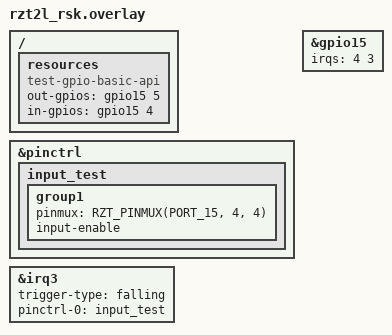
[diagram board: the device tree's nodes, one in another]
/*
 * Copyright (c) 2025 Renesas Electronics Corporation
 * SPDX-License-Identifier: Apache-2.0
 */

/ {
	resources {
		compatible = "test-gpio-basic-api";
		out-gpios = <&gpio15 5 GPIO_ACTIVE_HIGH>;
		in-gpios = <&gpio15 4 GPIO_ACTIVE_HIGH>;
	};
};

&pinctrl {
	input_test: input_test{
		group1 {
			pinmux = <RZT_PINMUX(PORT_15, 4, 4)>;
			input-enable;
		};
	};
};

&irq3 {
	trigger-type = "falling";
	pinctrl-0 = <&input_test>;
	pinctrl-names = "default";
	status = "okay";
};

&gpio15 {
	irqs = <4 3>;
	status = "okay";
};
